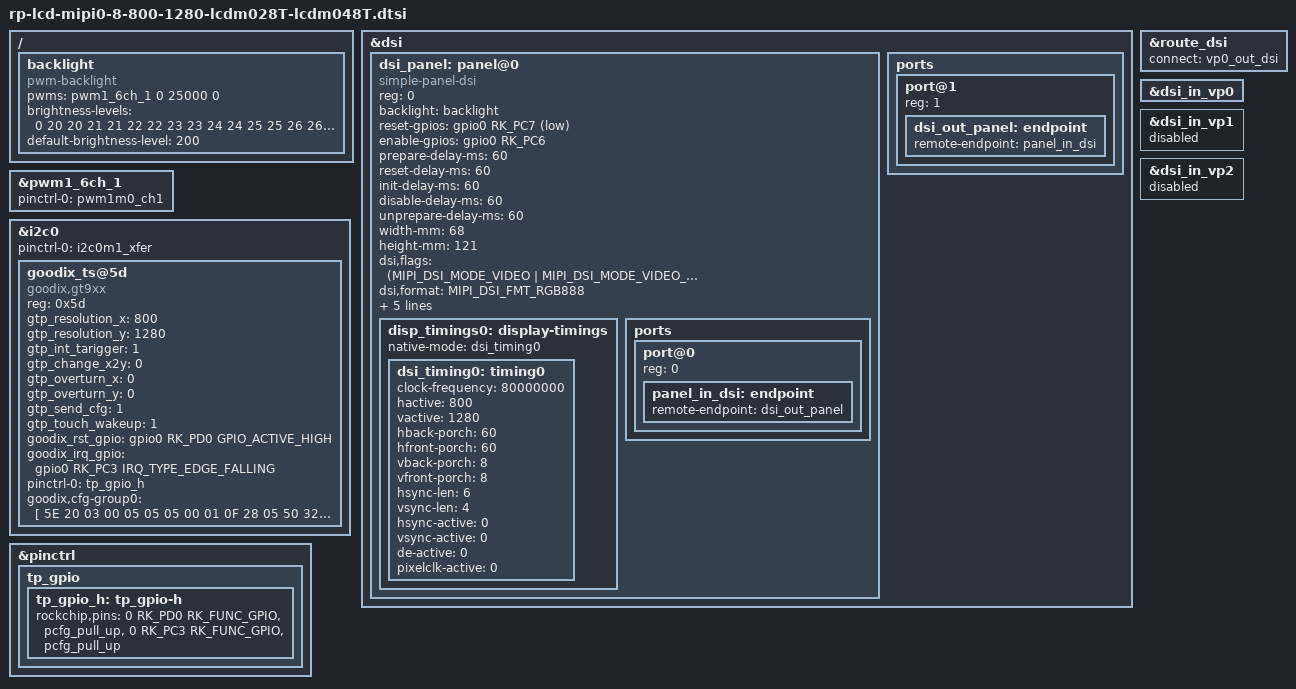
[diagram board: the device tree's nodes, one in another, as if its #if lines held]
/{
    backlight: backlight {
        compatible = "pwm-backlight";
        pwms = <&pwm1_6ch_1 0 25000 0>;
        brightness-levels = <
              0  20  20  21  21  22  22  23
             23  24  24  25  25  26  26  27
             27  28  28  29  29  30  30  31
             31  32  32  33  33  34  34  35
             35  36  36  37  37  38  38  39
             40  41  42  43  44  45  46  47
             48  49  50  51  52  53  54  55
             56  57  58  59  60  61  62  63
             64  65  66  67  68  69  70  71
             72  73  74  75  76  77  78  79
             80  81  82  83  84  85  86  87
             88  89  90  91  92  93  94  95
             96  97  98  99 100 101 102 103
            104 105 106 107 108 109 110 111
            112 113 114 115 116 117 118 119
            120 121 122 123 124 125 126 127
            128 129 130 131 132 133 134 135
            136 137 138 139 140 141 142 143
            144 145 146 147 148 149 150 151
            152 153 154 155 156 157 158 159
            160 161 162 163 164 165 166 167
            168 169 170 171 172 173 174 175
            176 177 178 179 180 181 182 183
            184 185 186 187 188 189 190 191
            192 193 194 195 196 197 198 199
            200 201 202 203 204 205 206 207
            208 209 210 211 212 213 214 215
            216 217 218 219 220 221 222 223
            224 225 226 227 228 229 230 231
            232 233 234 235 236 237 238 239
            240 241 242 243 244 245 246 247
            248 249 250 251 252 253 254 255
        >;
        default-brightness-level = <200>;
    };
};


&dsi {
    status = "okay";
    //rockchip,lane-rate = <480>;
    dsi_panel: panel@0 {
        status = "okay";
        compatible = "simple-panel-dsi";
        reg = <0>;
        backlight = <&backlight>;
        
        reset-gpios = <&gpio0 RK_PC7 GPIO_ACTIVE_LOW>;
        enable-gpios = <&gpio0 RK_PC6 GPIO_ACTIVE_HIGH>;
        
        prepare-delay-ms = <60>;
        reset-delay-ms = <60>;
        init-delay-ms = <60>;
        disable-delay-ms = <60>;
        unprepare-delay-ms = <60>;
        width-mm = <68>;
        height-mm = <121>;
        dsi,flags = <(MIPI_DSI_MODE_VIDEO | MIPI_DSI_MODE_VIDEO_BURST |
                  MIPI_DSI_MODE_LPM | MIPI_DSI_MODE_NO_EOT_PACKET)>;
        dsi,format = <MIPI_DSI_FMT_RGB888>;
        dsi,lanes  = <4>;

        panel-init-sequence = [
			39 00 02 e0 00
			39 00 02 e1 93
			39 00 02 e2 65
			39 00 02 e3 f8
			39 00 02 80 03
			//39 00 02 Page 1 */
			39 00 02 e0 01
			39 00 02 00 00
			39 00 02 01 4e
			39 00 02 03 00
			39 00 02 04 65
			39 00 02 0c 74
			39 00 02 17 00
			39 00 02 18 b7
			39 00 02 19 00
			39 00 02 1a 00
			39 00 02 1b b7
			39 00 02 1c 00
			39 00 02 24 fe
			39 00 02 37 19
			39 00 02 38 05
			39 00 02 39 00
			39 00 02 3a 01
			39 00 02 3b 01
			39 00 02 3c 70
			39 00 02 3d ff
			39 00 02 3e ff
			39 00 02 3f ff
			39 00 02 40 06
			39 00 02 41 a0
			39 00 02 43 1e
			39 00 02 44 0f
			39 00 02 45 28
			39 00 02 4b 04
			39 00 02 55 02
			39 00 02 56 01
			39 00 02 57 a9
			39 00 02 58 0a
			39 00 02 59 0a
			39 00 02 5a 37
			39 00 02 5b 19
			//39 00 02 Positive Gamma */
			39 00 02 5d 78
			39 00 02 5e 63
			39 00 02 5f 54
			39 00 02 60 49
			39 00 02 61 45
			39 00 02 62 38
			39 00 02 63 3d
			39 00 02 64 28
			39 00 02 65 43
			39 00 02 66 41
			39 00 02 67 43
			39 00 02 68 62
			39 00 02 69 50
			39 00 02 6a 57
			39 00 02 6b 49
			39 00 02 6c 44
			39 00 02 6d 37
			39 00 02 6e 23
			39 00 02 6f 10
			//39 00 02 Negative Gamma */
			39 00 02 70 78
			39 00 02 71 63
			39 00 02 72 54
			39 00 02 73 49
			39 00 02 74 45
			39 00 02 75 38
			39 00 02 76 3d
			39 00 02 77 28
			39 00 02 78 43
			39 00 02 79 41
			39 00 02 7a 43
			39 00 02 7b 62
			39 00 02 7c 50
			39 00 02 7d 57
			39 00 02 7e 49
			39 00 02 7f 44
			39 00 02 80 37
			39 00 02 81 23
			39 00 02 82 10
			//39 00 02 Page 2 */
			39 00 02 e0 02
			39 00 02 00 47
			39 00 02 01 47
			39 00 02 02 45
			39 00 02 03 45
			39 00 02 04 4b
			39 00 02 05 4b
			39 00 02 06 49
			39 00 02 07 49
			39 00 02 08 41
			39 00 02 09 1f
			39 00 02 0a 1f
			39 00 02 0b 1f
			39 00 02 0c 1f
			39 00 02 0d 1f
			39 00 02 0e 1f
			39 00 02 0f 5f
			39 00 02 10 5f
			39 00 02 11 57
			39 00 02 12 77
			39 00 02 13 35
			39 00 02 14 1f
			39 00 02 15 1f
			39 00 02 16 46
			39 00 02 17 46
			39 00 02 18 44
			39 00 02 19 44
			39 00 02 1a 4a
			39 00 02 1b 4a
			39 00 02 1c 48
			39 00 02 1d 48
			39 00 02 1e 40
			39 00 02 1f 1f
			39 00 02 20 1f
			39 00 02 21 1f
			39 00 02 22 1f
			39 00 02 23 1f
			39 00 02 24 1f
			39 00 02 25 5f
			39 00 02 26 5f
			39 00 02 27 57
			39 00 02 28 77
			39 00 02 29 35
			39 00 02 2a 1f
			39 00 02 2b 1f
			39 00 02 58 40
			39 00 02 59 00
			39 00 02 5a 00
			39 00 02 5b 10
			39 00 02 5c 06
			39 00 02 5d 40
			39 00 02 5e 01
			39 00 02 5f 02
			39 00 02 60 30
			39 00 02 61 01
			39 00 02 62 02
			39 00 02 63 03
			39 00 02 64 6b
			39 00 02 65 05
			39 00 02 66 0c
			39 00 02 67 73
			39 00 02 68 09
			39 00 02 69 03
			39 00 02 6a 56
			39 00 02 6b 08
			39 00 02 6c 00
			39 00 02 6d 04
			39 00 02 6e 04
			39 00 02 6f 88
			39 00 02 70 00
			39 00 02 71 00
			39 00 02 72 06
			39 00 02 73 7b
			39 00 02 74 00
			39 00 02 75 f8
			39 00 02 76 00
			39 00 02 77 d5
			39 00 02 78 2e
			39 00 02 79 12
			39 00 02 7a 03
			39 00 02 7b 00
			39 00 02 7c 00
			39 00 02 7d 03
			39 00 02 7e 7b
			39 00 02 e0 04
			39 00 02 00 0e
			39 00 02 02 b3
			39 00 02 09 60
			39 00 02 0e 2a
			39 00 02 36 59
			39 00 02 e0 00
			05 78 01 11
			05 78 01 29
			39 00 02 35 00
		];
		/* Panel De-initialization Sequence */
		panel-exit-sequence = [
			05 78 01 11
			05 00 01 28
		];

        disp_timings0: display-timings {
            native-mode = <&dsi_timing0>;
            dsi_timing0: timing0 {
                clock-frequency = <80000000>;
                hactive = <800>;
                vactive = <1280>;
                hback-porch = <60>;
                hfront-porch = <60>;
                vback-porch = <8>;
                vfront-porch = <8>;
                hsync-len = <6>;
                vsync-len = <4>;
                hsync-active = <0>;
                vsync-active = <0>;
                de-active = <0>;
                pixelclk-active = <0>;
            };
        };

        ports {
            #address-cells = <1>;
            #size-cells = <0>;

            port@0 {
                reg = <0>;
                panel_in_dsi: endpoint {
                    remote-endpoint = <&dsi_out_panel>;
                };
            };
        };
    };

    ports {
        #address-cells = <1>;
        #size-cells = <0>;

        port@1 {
            reg = <1>;
            dsi_out_panel: endpoint {
                remote-endpoint = <&panel_in_dsi>;
            };
        };
    };

};


#if defined RP_RK3576S || defined DR4_RK3576X || defined PRO_RK3576X

&route_dsi {
    status = "okay";
    connect = <&vp0_out_dsi>;
};

&pwm1_6ch_1 {
    status = "okay";
    pinctrl-0 = <&pwm1m0_ch1>;
};

&dsi_in_vp0 {
    status = "okay";
};

&dsi_in_vp1 {
    status = "disabled";
};

&dsi_in_vp2 {
    status = "disabled";
};


#else  //rk3576

&route_dsi {
    status = "okay";
};

&pwm1_6ch_1 {
    status = "okay";
    pinctrl-0 = <&pwm1m0_ch1>;
};

//default to hdmi
&dsi_in_vp0 {
    status = "disabled";
};

&dsi_in_vp1 {
    status = "okay";
};

&dsi_in_vp2 {
    status = "disabled";
};

&dsi_in_vopl {
    status = "okay";
};
#endif

//TP
&i2c0 {
    status = "okay";
    pinctrl-names = "default";
    pinctrl-0 = <&i2c0m1_xfer>;
    goodix_ts@5d {
        compatible = "goodix,gt9xx";
        reg = <0x5d>;
        gtp_resolution_x = <800>;
        gtp_resolution_y = <1280>;
        gtp_int_tarigger = <1>;
        gtp_change_x2y = <0>;
        gtp_overturn_x = <0>;
        gtp_overturn_y = <0>;
        gtp_send_cfg = <1>;
        gtp_touch_wakeup = <1>;
        goodix_rst_gpio = <&gpio0 RK_PD0 GPIO_ACTIVE_HIGH>;
        goodix_irq_gpio = <&gpio0 RK_PC3 IRQ_TYPE_EDGE_FALLING>;
        pinctrl-names = "default";
        pinctrl-0 = <&tp_gpio_h>;
        goodix,cfg-group0 = [
               5E 20 03 00 05 05 05 00 01 0F 28 
			   05 50 32 03 05 00 00 00 00 00 00 
			   00 00 00 00 00 8C 2C 0E 52 54 0C 
			   08 00 00 01 81 02 1C 00 00 00 00 
			   00 03 64 32 00 00 00 32 78 94 C5 
			   02 07 00 00 04 A3 36 00 91 41 00 
			   84 4D 00 79 5C 00 70 6E 00 70 00 
			   00 00 00 00 00 00 00 00 00 00 00 
			   00 00 00 00 00 00 00 00 00 00 00 
			   00 00 00 00 00 00 00 00 00 00 00 
			   00 00 1C 1A 18 16 14 12 10 0E 0C 
			   0A 08 06 04 02 00 00 00 00 00 00 
			   00 00 00 00 00 00 00 00 00 00 00 
			   02 04 06 08 0A 0C 0F 10 12 13 14 
			   28 26 24 22 21 20 1F 1E 1D 1C 18 
			   16 FF FF 00 00 00 00 00 00 00 00 
			   00 00 00 00 00 00 00 00 76 01
		];   
    };
};

&pinctrl {
    tp_gpio {
		tp_gpio_h: tp_gpio-h {
			rockchip,pins = <0 RK_PD0 RK_FUNC_GPIO &pcfg_pull_up>,
                            <0 RK_PC3 RK_FUNC_GPIO &pcfg_pull_up>;
		};
	};
};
